AUTOSAR XML (schema 4-3-1)
package /DoorControlSystem
  system DoorControlSystemModel
    sub-components:
      system mapping DoorControlECU_Mapping: enable-out-of-order-delivery=false
    can communication connector CAN_Connector
      comm controller mapping CAN_Controller_Mapping: physical-channel=CAN_Channel
package /DoorControlSystem/ComponentTypes
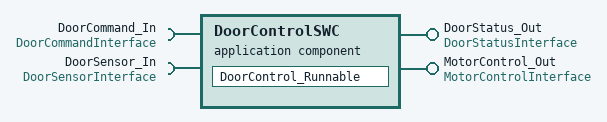
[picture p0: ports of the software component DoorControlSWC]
  application sw component type DoorControlSWC: category=APPLICATION_COMPONENT
    provide port DoorStatus_Out: provided-interface=DoorStatusInterface
    provide port MotorControl_Out: provided-interface=MotorControlInterface
    require port DoorCommand_In: required-interface=DoorCommandInterface
    require port DoorSensor_In: required-interface=DoorSensorInterface
    behavior DoorControlBehavior: enable-out-of-order-delivery=false
      timing event DoorControl_TE: disable-out-of-order-delivery-support=true, event-controlled-timing={number-of-repetitions=0, timing-event-processing=CYCLIC}, period=0.01, start-on-event=DoorControl_Runnable
      runnable DoorControl_Runnable: can-be-invoked-without-holding-lock=false
        data read access ReadDoorCommand: data-element=DoorCommand_In.DoorOpenCmd
        data write access WriteDoorStatus: data-element=DoorStatus_Out.DoorPosition
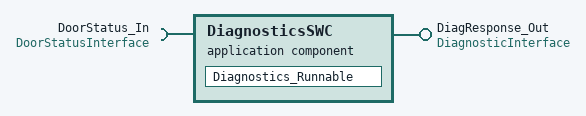
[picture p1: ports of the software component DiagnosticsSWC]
  application sw component type DiagnosticsSWC: category=APPLICATION_COMPONENT
    require port DoorStatus_In: required-interface=DoorStatusInterface
    provide port DiagResponse_Out: provided-interface=DiagnosticInterface
    behavior DiagnosticsBehavior: enable-out-of-order-delivery=false
      timing event Diagnostics_TE: disable-out-of-order-delivery-support=true, event-controlled-timing={number-of-repetitions=0, timing-event-processing=CYCLIC}, period=0.05, start-on-event=Diagnostics_Runnable
      runnable Diagnostics_Runnable: can-be-invoked-without-holding-lock=false
package /DoorControlSystem/Interfaces
  4 x sender receiver interface:
    DoorCommandInterface
      data DoorOpenCmd: type=DoorCommandType
      data DoorCloseCmd: type=DoorCommandType
    DoorStatusInterface
      data DoorPosition: type=DoorPositionType
      data DoorStatus: type=DoorStatusType
      data DoorError: type=DoorErrorType
    DoorSensorInterface
      data SensorPosition: type=SensorPositionType
      data MotorCurrent: type=CurrentType
    DiagnosticInterface
      data DIDValue: type=DIDValueType
  client server interface MotorControlInterface
    operation SetMotorSpeed
      arg Speed: type=MotorSpeedType
package /DoorControlSystem/CAN_Network
  can cluster CAN_Cluster: baudrate=500000
    can physical channel CAN_Channel
      frame DoorCommand_Frame: id 0x100, frame-length=8
        carries pdu DoorCommand_PDU: packing-byte-order=little-endian, start-position=0
      frame DoorStatus_Frame: id 0x101, frame-length=8
        carries pdu DoorStatus_PDU: packing-byte-order=little-endian, start-position=0
      frame Diagnostics_Frame: id 0x7D0, frame-length=8
        carries pdu Diagnostics_PDU: packing-byte-order=little-endian, start-position=0
